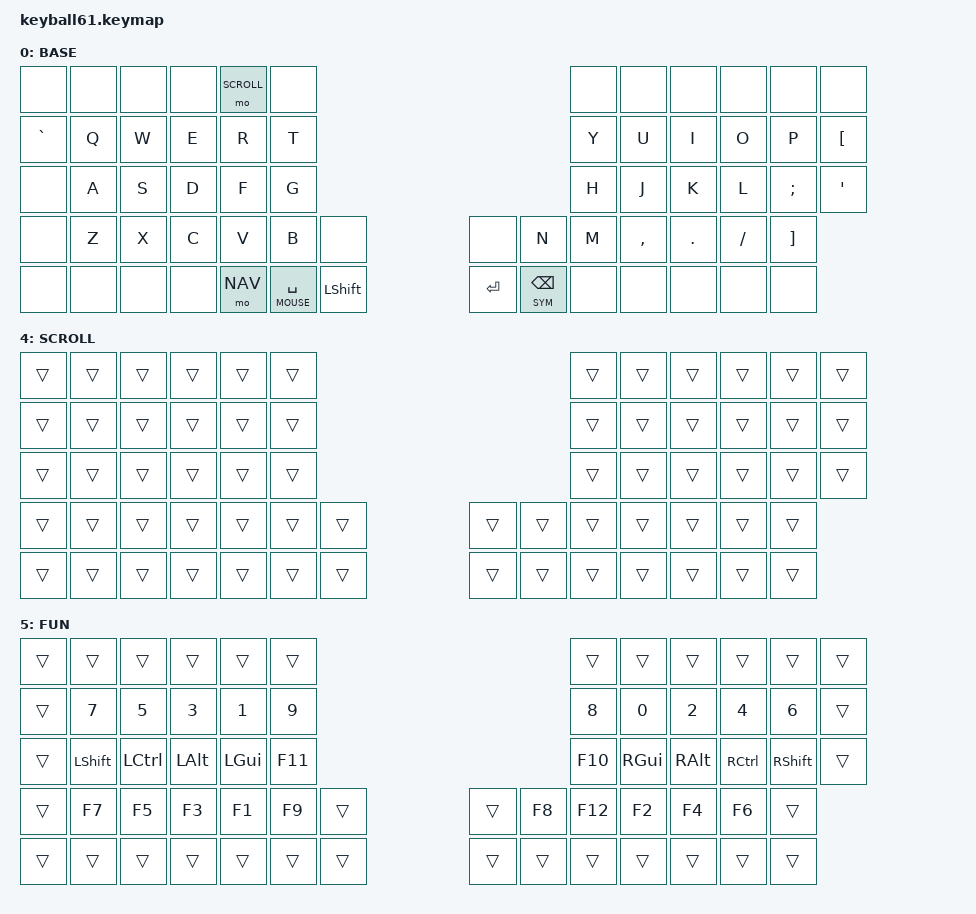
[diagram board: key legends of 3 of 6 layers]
#include <behaviors.dtsi>
#include <dt-bindings/zmk/keys.h>
#include <dt-bindings/zmk/bt.h>
#include <dt-bindings/zmk/mouse.h>

#define BASE 0
#define NAV 1
#define SYM 2
#define MOUSE 3
#define SCROLL 4
#define FUN 5

&caps_word {
    continue-list = <UNDERSCORE MINUS BSPC DEL>;
};

&lt {
    flavor = "balanced";
    tapping-term-ms = <200>;
    quick-tap-ms = <175>;
};

&mt {
    flavor = "balanced";
    tapping-term-ms = <200>;
    quick-tap-ms = <175>;
};

/ {
    conditional_layers {
        compatible = "zmk,conditional-layers";
        fun_layer {
            if-layers = <SYM MOUSE>;
            then-layer = <FUN>;
        };
    };

    behaviors {
        skq: sticky_key_quick_release {
            compatible = "zmk,behavior-sticky-key";
            label = "STICKY_KEY_QUICK";
            #binding-cells = <1>;
            bindings = <&kp>;
            release-after-ms = <2000>;
            quick-release;
            ignore-modifiers;
        };

        lt_mouse: layer_tap_mouse {
            compatible = "zmk,behavior-hold-tap";
            label = "LAYER_TAP_MOUSE";
            #binding-cells = <2>;
            flavor = "balanced";
            tapping-term-ms = <200>;
            quick-tap-ms = <175>;
            bindings = <&mo>, <&kp>;
        };
    };

    macros {
        swapper: swapper {
            compatible = "zmk,behavior-macro";
            label = "SWAPPER";
            #binding-cells = <0>;
            bindings
                = <&macro_press &kp LGUI>
                , <&macro_tap &kp TAB>
                , <&macro_pause_for_release>
                , <&macro_release &kp LGUI>;
        };
        
        swapper_win: swapper_win {
            compatible = "zmk,behavior-macro";
            label = "SWAPPER_WIN";
            #binding-cells = <0>;
            bindings
                = <&macro_press &kp LGUI>
                , <&macro_tap &kp GRAVE>
                , <&macro_pause_for_release>
                , <&macro_release &kp LGUI>;
        };
    };

    keymap {
        compatible = "zmk,keymap";

        base_layer {
            label = "BASE";
            bindings = <
&none      &none      &none      &none      &mo SCROLL     &none                                      &none      &none      &none      &none      &none      &none
&kp GRAVE  &kp Q      &kp W      &kp E      &kp R      &kp T                                      &kp Y      &kp U      &kp I      &kp O      &kp P      &kp LBKT
&none      &kp A      &kp S      &kp D      &kp F      &kp G                                      &kp H      &kp J      &kp K      &kp L      &kp SEMI   &kp SQT
&none      &kp Z      &kp X      &kp C      &kp V      &kp B      &none            &none      &kp N      &kp M      &kp COMMA  &kp DOT    &kp FSLH   &kp RBKT
&none      &none      &none      &none      &mo NAV    &lt_mouse MOUSE SPACE &kp LSHFT &kp RET    &lt SYM BSPC &none      &none      &none      &none      &none
            >;
        };

        nav_layer {
            label = "NAV";
            bindings = <
&none &none        &none         &none        &none         &none                                      &none     &none      &none      &none      &none      &none
&none &none        &kp TAB       &kp LC(LS(TAB)) &kp LC(TAB) &kp C_VOL_UP                              &none     &kp PG_UP  &kp UP    &kp PG_DN    &none    &none
&none &skq LSHFT   &skq LCTRL    &skq LALT       &skq LGUI   &kp C_VOL_DN                              &none     &kp LEFT   &kp DOWN   &kp RIGHT  &none      &none
&none &none        &kp C_FF      &kp C_FF        &kp ESC     &kp C_PP    &none                &sys_reset &none     &caps_word      &swapper_win &none    &none      &none
&none &none        &none         &none        &none         &none           &trans      &trans       &trans   &trans &trans       &kp BSPC   &none      &none      &none      &none      &none
            >;
        };

        sym_layer {
            label = "SYM";
            bindings = <
&none &none     &none     &none     &none     &none                                      &none      &none      &none      &none      &none      &none
&none &none     &kp LBKT  &kp LBRC  &kp LPAR  &kp TILDE                                  &kp CARET  &kp RPAR   &kp RBRC   &kp RBKT   &kp GRAVE  &none
&none &kp MINUS &kp STAR  &kp EQUAL &kp UNDER &kp DLLR                                   &kp HASH   &skq RGUI  &skq RALT  &skq RCTRL &skq RSHFT &none
&none &kp PLUS  &kp PIPE  &kp AT    &kp FSLH  &kp PRCNT  &none        &none &kp BSLH   &kp AMPS   &kp QMARK  &kp EXCL   &none      &none
&none &none     &none     &none     &mo NAV   &lt_mouse MOUSE SPACE &kp LSHFT &trans &trans &none      &none      &none      &none      &none      &none      &none
            >;
        };

        mouse_layer {
            label = "MOUSE";
            bindings = <
&none &none      &none      &none      &none      &none                                                &none      &none      &none      &none      &none      &none
&none &none      &none      &none      &none      &none                                                &none      &none      &none      &none      &none      &none
&none &skq LSHFT &skq LCTRL &skq LALT  &skq LGUI  &none                                                &none      &mkp LCLK  &mkp RCLK  &mkp MCLK  &none      &none
&none &none      &none      &none      &none      &none      &none             &none      &none      &none      &none      &none      &none      &none
&none &none      &none      &none      &trans     &trans     &trans   &mkp LCLK &lt SYM BSPC &none      &none      &none      &none      &none      &none
            >;
        };

        scroll_layer {
            label = "SCROLL";
            bindings = <
&trans &trans &trans &trans &trans &trans                                 &trans &trans &trans &trans &trans &trans
&trans &trans &trans &trans &trans &trans                                 &trans &trans &trans &trans &trans &trans
&trans &trans &trans &trans &trans &trans                                 &trans &trans &trans &trans &trans &trans
&trans &trans &trans &trans &trans &trans &trans            &trans &trans &trans &trans &trans &trans &trans
&trans &trans &trans &trans &trans &trans &trans            &trans &trans &trans &trans &trans &trans &trans
            >;
        };

        fun_layer {
            label = "FUN";
            bindings = <
&trans &trans    &trans    &trans    &trans    &trans                                   &trans     &trans     &trans     &trans     &trans     &trans
&trans &kp N7    &kp N5    &kp N3    &kp N1    &kp N9                                   &kp N8     &kp N0     &kp N2     &kp N4     &kp N6     &trans
&trans &kp LSHFT &kp LCTRL &kp LALT  &kp LGUI  &kp F11                                  &kp F10    &kp RGUI   &kp RALT   &kp RCTRL  &kp RSHFT  &trans
&trans &kp F7    &kp F5    &kp F3    &kp F1    &kp F9    &trans               &trans    &kp F8     &kp F12    &kp F2     &kp F4     &kp F6     &trans
&trans &trans    &trans    &trans    &trans    &trans    &trans               &trans    &trans     &trans     &trans     &trans     &trans     &trans
            >;
        };
    };
};
